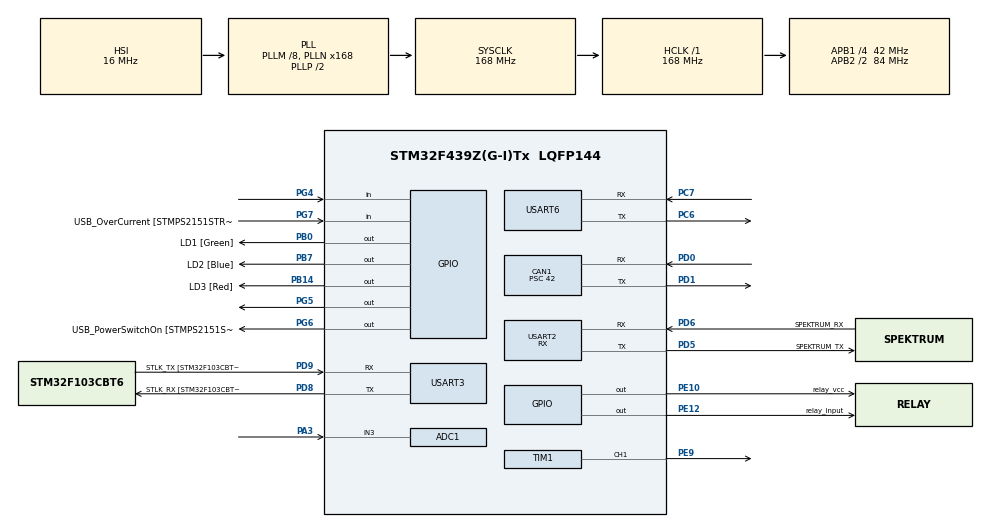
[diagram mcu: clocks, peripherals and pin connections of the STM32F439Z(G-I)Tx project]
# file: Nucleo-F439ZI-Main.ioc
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ADC1.Channel-2\#ChannelRegularConversion=ADC_CHANNEL_3
ADC1.NbrOfConversionFlag=1
ADC1.Rank-2\#ChannelRegularConversion=1
ADC1.SamplingTime-2\#ChannelRegularConversion=ADC_SAMPLETIME_3CYCLES
ADC1.master=1
CAN1.ABOM=ENABLE
CAN1.AWUM=ENABLE
CAN1.BS1=CAN_BS1_11TQ
CAN1.BS2=CAN_BS2_8TQ
CAN1.CalculateBaudRate=50000
CAN1.CalculateTimeBit=20000
CAN1.CalculateTimeQuantum=1000.0
CAN1.NART=ENABLE
CAN1.Prescaler=42
CAN1.TTCM=DISABLE
Mcu.Family=STM32F4
Mcu.Name=STM32F439Z(G-I)Tx
Mcu.Package=LQFP144
NVIC.CAN1_RX0_IRQn=true\:0\:0\:false\:false\:true\:true\:true\:true
NVIC.CAN1_RX1_IRQn=true\:0\:0\:false\:false\:true\:true\:true\:true
NVIC.CAN1_SCE_IRQn=true\:0\:0\:false\:false\:true\:true\:true\:true
NVIC.CAN1_TX_IRQn=true\:0\:0\:false\:false\:true\:true\:true\:true
NVIC.PriorityGroup=NVIC_PRIORITYGROUP_4
NVIC.RCC_IRQn=true\:0\:0\:false\:false\:true\:true\:false\:true
NVIC.TIM6_DAC_IRQn=true\:0\:0\:false\:false\:true\:true\:true\:true
NVIC.USART2_IRQn=true\:1\:0\:true\:false\:true\:true\:true\:true
PA1.GPIO_Label=RMII_REF_CLK [LAN8742A-CZ-TR_REFCLK0]
PA1.Signal=ETH_REF_CLK
PA10.GPIO_Label=USB_ID
PA10.Signal=USB_OTG_FS_ID
PA11.GPIO_Label=USB_DM
PA11.Signal=USB_OTG_FS_DM
PA12.GPIO_Label=USB_DP
PA12.Signal=USB_OTG_FS_DP
PA13.GPIO_Label=TMS
PA13.Mode=Serial_Wire
PA13.Signal=SYS_JTMS-SWDIO
PA14.GPIO_Label=TCK
PA14.Mode=Serial_Wire
PA14.Signal=SYS_JTCK-SWCLK
PA2.GPIO_Label=RMII_MDIO [LAN8742A-CZ-TR_MDIO]
PA2.Signal=ETH_MDIO
PA3.Signal=ADCx_IN3
PA7.GPIO_Label=RMII_CRS_DV [LAN8742A-CZ-TR_CRS_DV]
PA7.Signal=ETH_CRS_DV
PA8.GPIO_Label=USB_SOF [TP1]
PA8.Signal=USB_OTG_FS_SOF
PA9.GPIO_Label=USB_VBUS
PA9.Signal=USB_OTG_FS_VBUS
PB0.GPIO_Label=LD1 [Green]
PB0.Signal=GPIO_Output
PB13.GPIO_Label=RMII_TXD1 [LAN8742A-CZ-TR_TXD1]
PB13.Signal=ETH_TXD1
PB14.GPIO_Label=LD3 [Red]
PB14.Signal=GPIO_Output
PB7.GPIO_Label=LD2 [Blue]
PB7.Signal=GPIO_Output
PC1.GPIO_Label=RMII_MDC [LAN8742A-CZ-TR_MDC]
PC1.Signal=ETH_MDC
PC14/OSC32_IN.Mode=LSE-External-Oscillator
PC14/OSC32_IN.Signal=RCC_OSC32_IN
PC15/OSC32_OUT.Mode=LSE-External-Oscillator
PC15/OSC32_OUT.Signal=RCC_OSC32_OUT
PC4.GPIO_Label=RMII_RXD0 [LAN8742A-CZ-TR_RXD0]
PC4.Signal=ETH_RXD0
PC5.GPIO_Label=RMII_RXD1 [LAN8742A-CZ-TR_RXD1]
PC5.Signal=ETH_RXD1
PC6.Mode=Asynchronous
PC6.Signal=USART6_TX
PC7.Mode=Asynchronous
PC7.Signal=USART6_RX
PD0.Mode=CAN_Activate
PD0.Signal=CAN1_RX
PD1.Mode=CAN_Activate
PD1.Signal=CAN1_TX
PD5.GPIO_Label=SPEKTRUM_TX
PD5.Mode=Asynchronous
PD5.Signal=USART2_TX
PD6.GPIO_Label=SPEKTRUM_RX
PD6.Mode=Asynchronous
PD6.Signal=USART2_RX
PD8.GPIO_Label=STLK_RX [STM32F103CBT6_PA3]
PD8.Mode=Asynchronous
PD8.Signal=USART3_TX
PD9.GPIO_Label=STLK_TX [STM32F103CBT6_PA2]
PD9.Mode=Asynchronous
PD9.Signal=USART3_RX
PE10.GPIO_Label=relay_vcc
PE10.Signal=GPIO_Output
PE12.GPIO_Label=relay_input
PE12.Signal=GPIO_Output
PE9.Signal=S_TIM1_CH1
PG11.GPIO_Label=RMII_TX_EN [LAN8742A-CZ-TR_TXEN]
PG11.Signal=ETH_TX_EN
PG13.GPIO_Label=RMII_TXD0 [LAN8742A-CZ-TR_TXD0]
PG13.Signal=ETH_TXD0
PG4.Signal=GPIO_Input
PG5.Signal=GPIO_Output
PG6.GPIO_Label=USB_PowerSwitchOn [STMPS2151STR_EN]
PG6.Signal=GPIO_Output
PG7.GPIO_Label=USB_OverCurrent [STMPS2151STR_FAULT]
PG7.Signal=GPIO_Input
PH0/OSC_IN.GPIO_Label=MCO [STM32F103CBT6_PA8]
PH0/OSC_IN.Mode=HSE-External-Clock-Source
PH0/OSC_IN.Signal=RCC_OSC_IN
PH1/OSC_OUT.Mode=HSE-External-Clock-Source
PH1/OSC_OUT.Signal=RCC_OSC_OUT
ProjectManager.HeapSize=0x200
ProjectManager.StackSize=0x400
ProjectManager.TargetToolchain=STM32CubeIDE
RCC.48MHZClocksFreq_Value=48000000
RCC.AHBFreq_Value=168000000
RCC.APB1CLKDivider=RCC_HCLK_DIV4
RCC.APB1Freq_Value=42000000
RCC.APB1TimFreq_Value=84000000
RCC.APB2CLKDivider=RCC_HCLK_DIV2
RCC.APB2Freq_Value=84000000
RCC.APB2TimFreq_Value=168000000
RCC.CortexFreq_Value=168000000
RCC.HCLKFreq_Value=168000000
RCC.HSE_VALUE=8000000
RCC.HSI_VALUE=16000000
RCC.PLLM=8
RCC.PLLMUL=RCC_PLL_MUL9
RCC.PLLN=168
RCC.PLLQ=7
RCC.PRESCALERUSB=RCC_USBCLKSOURCE_PLL_DIV1_5
RCC.SYSCLKFreq_VALUE=168000000
RCC.SYSCLKSource=RCC_SYSCLKSOURCE_PLLCLK
RCC.SYSCLKSourceVirtual=RCC_SYSCLKSOURCE_PLLCLK
RCC.USBFreq_Value=48000000
RCC.VCOOutputFreq_Value=336000000
SH.ADCx_IN3.0=ADC1_IN3,IN3
SH.S_TIM1_CH1.0=TIM1_CH1,PWM Generation1 CH1
TIM1.Channel-PWM\ Generation1\ CH1=TIM_CHANNEL_1
TIM1.Period=200-1
TIM1.Prescaler=3*168-1
TIM6.AutoReloadPreload=TIM_AUTORELOAD_PRELOAD_DISABLE
TIM6.Period=10000
TIM6.Prescaler=168-1
USART2.Mode=MODE_RX
USART2.VirtualMode=VM_ASYNC
USART3.VirtualMode=VM_ASYNC
USART6.VirtualMode=VM_ASYNC
VP_TIM6_VS_ClockSourceINT.Mode=Enable_Timer
board=NUCLEO-F439ZI

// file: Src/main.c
/* USER CODE BEGIN Header */
/**
  ******************************************************************************
  * @file           : main.c
  * @brief          : Main program body
  ******************************************************************************
  * @attention
  *
  * Copyright (c) 2022 STMicroelectronics.
  * All rights reserved.
  *
  * This software is licensed under terms that can be found in the LICENSE file
  * in the root directory of this software component.
  * If no LICENSE file comes with this software, it is provided AS-IS.
  *
  ******************************************************************************
  */
/* USER CODE END Header */
#include "main.h"

/* USER CODE BEGIN Includes */
#include <stdio.h>
#include "app.h"
#include "av_com.h"

#include "terminal.h"
#include "utils.h"
#include "endianness.h"
/* USER CODE END Includes */

ADC_HandleTypeDef hadc1;

CAN_HandleTypeDef hcan1;

TIM_HandleTypeDef htim1;
TIM_HandleTypeDef htim6;

UART_HandleTypeDef huart2;
UART_HandleTypeDef huart3;
UART_HandleTypeDef huart6;

/* USER CODE BEGIN PV */
int throttle;
int throttle_min = 50;
int throttle_max = 2800;

float acc_percent;
float acc_limit = 0.5;

int speed_suppress_count = 0;
int speed_suppress_low = 3;
int speed_suppress_high = 5;

app_state_t app;
app_state_t *main_app;

CAN_TxHeaderTypeDef TxHeader;
CAN_RxHeaderTypeDef RxHeader;

uint32_t TxMailbox;

uint8_t TxData[8];
uint8_t RxData[8];

uint8_t UART_Rx_data[10];

/* USER CODE END PV */

void SystemClock_Config(void);
static void MX_GPIO_Init(void);
static void MX_USART3_UART_Init(void);
static void MX_USART2_UART_Init(void);
static void MX_TIM1_Init(void);
static void MX_CAN1_Init(void);
static void MX_ADC1_Init(void);
static void MX_USART6_UART_Init(void);
static void MX_TIM6_Init(void);

/* USER CODE BEGIN 0 */

int Debug_UART_Get_Byte() {
	if (__HAL_UART_GET_FLAG(&huart3, UART_FLAG_RXNE) == SET) {
		return (uint8_t) (huart3.Instance->DR & (uint8_t) 0x00FF);
	}
	return -1;
}

void HAL_TIM_PeriodElapsedCallback(TIM_HandleTypeDef *htim) {
	if (htim == &htim6) {
	  // get remote control speed
	  acc_percent = app.acc_percent;

	  if (acc_percent < -0.6){
		  TxData[1] = (int)0;
	  }
	  if (acc_percent >= -0.6 && acc_percent < -0.2){
		  TxData[1] = (int)1;
	  }
	  if (acc_percent >= -0.2){
		  TxData[1] = (int)2;
	  }

	  if (acc_percent < 0.00){
		  acc_percent = 0.00;
	  }

	  if (acc_percent > 1.00){
		  acc_percent = 1.00;
	  }

	  speed_suppress_count += 1;

	  if (speed_suppress_count < speed_suppress_low){
		  TIM1->CCR1 = 138 - 138 * acc_percent * acc_limit;
	  }
	  else if(speed_suppress_count < speed_suppress_high){
		  TIM1->CCR1 = 138;
	  }
	  else{
		  TIM1->CCR1 = 138;
		  speed_suppress_count = 0;
	  }

	  HAL_TIM_PWM_Start(&htim1, TIM_CHANNEL_1);

	  // send steer command over can bus
	  TxData[0] = (int)app.steering_angle;

	  // printf("steering angle desired %d \r\n", TxData[0]);

	  HAL_CAN_AddTxMessage(&hcan1, &TxHeader, TxData, &TxMailbox);
  }
}

/* USER CODE END 0 */

int main(void)
{

  /* MCU Configuration--------------------------------------------------------*/

  /* Reset of all peripherals, Initializes the Flash interface and the Systick. */
  HAL_Init();

  /* Configure the system clock */
  SystemClock_Config();

  /* Initialize all configured peripherals */
  MX_GPIO_Init();
  MX_USART3_UART_Init();
  MX_USART2_UART_Init();
  MX_TIM1_Init();
  MX_CAN1_Init();
  MX_ADC1_Init();
  MX_USART6_UART_Init();
  MX_TIM6_Init();
  /* USER CODE BEGIN 2 */

  main_app = &app;
  app_run(&app);

  HAL_TIM_Base_Start_IT(&htim6);
  av_com_start_receiving(&huart6);

  HAL_Delay(1000);

  /* USER CODE END 2 */

  /* Infinite loop */
  /* USER CODE BEGIN WHILE */
  while (1)
  {
//	  int temp = HAL_GPIO_ReadPin(GPIOG, Speed_Sensor_Pin);
//	  debug_printf("wheel speed sensor %d \r\n", temp);

//	  uint8_t message[] = "Hello World!!!"; //Data to send
//	  send_vehicle_status(&huart6, message, 14);
//	  HAL_Delay(200);
//
//	  int i;
//	  for (i=0;i < (sizeof (data_frame) /sizeof (data_frame[0]));i++) {
//	      debug_printf("%c",data_frame[i]);
//	  }
//	  debug_printf("\r\n");

	  if (1){
		 // Get throttle value
		  HAL_ADC_Start(&hadc1);
		  HAL_ADC_PollForConversion(&hadc1, HAL_MAX_DELAY);
		  throttle = HAL_ADC_GetValue(&hadc1);
		  acc_percent = (throttle_max - throttle) * 1.0 / (throttle_max - throttle_min) * 1.0;
		  acc_percent = 1.0 - acc_percent;

		  debug_printf("throttle %d \r\n", throttle);
	  } else{
//		  get remote control speed
		  acc_percent = app.acc_percent;
	  }
    /* USER CODE END WHILE */
  }

}

void SystemClock_Config(void)
{
  RCC_OscInitTypeDef RCC_OscInitStruct = {0};
  RCC_ClkInitTypeDef RCC_ClkInitStruct = {0};

  /** Configure the main internal regulator output voltage
  */
  __HAL_RCC_PWR_CLK_ENABLE();
  __HAL_PWR_VOLTAGESCALING_CONFIG(PWR_REGULATOR_VOLTAGE_SCALE1);

  /** Initializes the RCC Oscillators according to the specified parameters
  * in the RCC_OscInitTypeDef structure.
  */
  RCC_OscInitStruct.OscillatorType = RCC_OSCILLATORTYPE_HSI;
  RCC_OscInitStruct.HSIState = RCC_HSI_ON;
  RCC_OscInitStruct.HSICalibrationValue = RCC_HSICALIBRATION_DEFAULT;
  RCC_OscInitStruct.PLL.PLLState = RCC_PLL_ON;
  RCC_OscInitStruct.PLL.PLLSource = RCC_PLLSOURCE_HSI;
  RCC_OscInitStruct.PLL.PLLM = 8;
  RCC_OscInitStruct.PLL.PLLN = 168;
  RCC_OscInitStruct.PLL.PLLP = RCC_PLLP_DIV2;
  RCC_OscInitStruct.PLL.PLLQ = 7;
  if (HAL_RCC_OscConfig(&RCC_OscInitStruct) != HAL_OK)
  {
    Error_Handler();
  }

  /** Initializes the CPU, AHB and APB buses clocks
  */
  RCC_ClkInitStruct.ClockType = RCC_CLOCKTYPE_HCLK|RCC_CLOCKTYPE_SYSCLK
                              |RCC_CLOCKTYPE_PCLK1|RCC_CLOCKTYPE_PCLK2;
  RCC_ClkInitStruct.SYSCLKSource = RCC_SYSCLKSOURCE_PLLCLK;
  RCC_ClkInitStruct.AHBCLKDivider = RCC_SYSCLK_DIV1;
  RCC_ClkInitStruct.APB1CLKDivider = RCC_HCLK_DIV4;
  RCC_ClkInitStruct.APB2CLKDivider = RCC_HCLK_DIV2;

  if (HAL_RCC_ClockConfig(&RCC_ClkInitStruct, FLASH_LATENCY_5) != HAL_OK)
  {
    Error_Handler();
  }
}

static void MX_ADC1_Init(void)
{

  ADC_ChannelConfTypeDef sConfig = {0};

  /** Configure the global features of the ADC (Clock, Resolution, Data Alignment and number of conversion)
  */
  hadc1.Instance = ADC1;
  hadc1.Init.ClockPrescaler = ADC_CLOCK_SYNC_PCLK_DIV4;
  hadc1.Init.Resolution = ADC_RESOLUTION_12B;
  hadc1.Init.ScanConvMode = DISABLE;
  hadc1.Init.ContinuousConvMode = DISABLE;
  hadc1.Init.DiscontinuousConvMode = DISABLE;
  hadc1.Init.ExternalTrigConvEdge = ADC_EXTERNALTRIGCONVEDGE_NONE;
  hadc1.Init.ExternalTrigConv = ADC_SOFTWARE_START;
  hadc1.Init.DataAlign = ADC_DATAALIGN_RIGHT;
  hadc1.Init.NbrOfConversion = 1;
  hadc1.Init.DMAContinuousRequests = DISABLE;
  hadc1.Init.EOCSelection = ADC_EOC_SINGLE_CONV;
  if (HAL_ADC_Init(&hadc1) != HAL_OK)
  {
    Error_Handler();
  }

  /** Configure for the selected ADC regular channel its corresponding rank in the sequencer and its sample time.
  */
  sConfig.Channel = ADC_CHANNEL_3;
  sConfig.Rank = 1;
  sConfig.SamplingTime = ADC_SAMPLETIME_3CYCLES;
  if (HAL_ADC_ConfigChannel(&hadc1, &sConfig) != HAL_OK)
  {
    Error_Handler();
  }

}

static void MX_CAN1_Init(void)
{

  /* USER CODE BEGIN CAN1_Init 0 */
  TxHeader.DLC = 4;
  TxHeader.ExtId = 0;
  TxHeader.IDE = CAN_ID_STD;
  TxHeader.RTR = CAN_RTR_DATA;
  TxHeader.StdId = 0x104;
  TxHeader.TransmitGlobalTime = DISABLE;

  /* USER CODE END CAN1_Init 0 */

  hcan1.Instance = CAN1;
  hcan1.Init.Prescaler = 42;
  hcan1.Init.Mode = CAN_MODE_NORMAL;
  hcan1.Init.SyncJumpWidth = CAN_SJW_1TQ;
  hcan1.Init.TimeSeg1 = CAN_BS1_11TQ;
  hcan1.Init.TimeSeg2 = CAN_BS2_8TQ;
  hcan1.Init.TimeTriggeredMode = DISABLE;
  hcan1.Init.AutoBusOff = ENABLE;
  hcan1.Init.AutoWakeUp = ENABLE;
  hcan1.Init.AutoRetransmission = ENABLE;
  hcan1.Init.ReceiveFifoLocked = DISABLE;
  hcan1.Init.TransmitFifoPriority = DISABLE;
  if (HAL_CAN_Init(&hcan1) != HAL_OK)
  {
    Error_Handler();
  }
  /* USER CODE BEGIN CAN1_Init 2 */

  CAN_FilterTypeDef canfilterconfig;

  canfilterconfig.FilterActivation = CAN_FILTER_ENABLE;
  canfilterconfig.FilterBank = 10;
  canfilterconfig.FilterFIFOAssignment = CAN_RX_FIFO0;
  canfilterconfig.FilterIdHigh = 0;
  canfilterconfig.FilterIdLow = 0x0000;
  canfilterconfig.FilterMaskIdHigh = 0;
  canfilterconfig.FilterMaskIdLow = 0x0000;
  canfilterconfig.FilterMode = CAN_FILTERMODE_IDMASK;
  canfilterconfig.FilterScale = CAN_FILTERSCALE_32BIT;
  canfilterconfig.SlaveStartFilterBank = 0;

  HAL_CAN_ConfigFilter(&hcan1, &canfilterconfig);
  HAL_CAN_Start(&hcan1);
  HAL_CAN_ActivateNotification(&hcan1, CAN_IT_RX_FIFO0_MSG_PENDING);

  /* USER CODE END CAN1_Init 2 */

}

static void MX_TIM1_Init(void)
{

  TIM_MasterConfigTypeDef sMasterConfig = {0};
  TIM_OC_InitTypeDef sConfigOC = {0};
  TIM_BreakDeadTimeConfigTypeDef sBreakDeadTimeConfig = {0};

  htim1.Instance = TIM1;
  htim1.Init.Prescaler = 3*168-1;
  htim1.Init.CounterMode = TIM_COUNTERMODE_UP;
  htim1.Init.Period = 200-1;
  htim1.Init.ClockDivision = TIM_CLOCKDIVISION_DIV1;
  htim1.Init.RepetitionCounter = 0;
  htim1.Init.AutoReloadPreload = TIM_AUTORELOAD_PRELOAD_DISABLE;
  if (HAL_TIM_PWM_Init(&htim1) != HAL_OK)
  {
    Error_Handler();
  }
  sMasterConfig.MasterOutputTrigger = TIM_TRGO_RESET;
  sMasterConfig.MasterSlaveMode = TIM_MASTERSLAVEMODE_DISABLE;
  if (HAL_TIMEx_MasterConfigSynchronization(&htim1, &sMasterConfig) != HAL_OK)
  {
    Error_Handler();
  }
  sConfigOC.OCMode = TIM_OCMODE_PWM1;
  sConfigOC.Pulse = 0;
  sConfigOC.OCPolarity = TIM_OCPOLARITY_HIGH;
  sConfigOC.OCNPolarity = TIM_OCNPOLARITY_HIGH;
  sConfigOC.OCFastMode = TIM_OCFAST_DISABLE;
  sConfigOC.OCIdleState = TIM_OCIDLESTATE_RESET;
  sConfigOC.OCNIdleState = TIM_OCNIDLESTATE_RESET;
  if (HAL_TIM_PWM_ConfigChannel(&htim1, &sConfigOC, TIM_CHANNEL_1) != HAL_OK)
  {
    Error_Handler();
  }
  sBreakDeadTimeConfig.OffStateRunMode = TIM_OSSR_DISABLE;
  sBreakDeadTimeConfig.OffStateIDLEMode = TIM_OSSI_DISABLE;
  sBreakDeadTimeConfig.LockLevel = TIM_LOCKLEVEL_OFF;
  sBreakDeadTimeConfig.DeadTime = 0;
  sBreakDeadTimeConfig.BreakState = TIM_BREAK_DISABLE;
  sBreakDeadTimeConfig.BreakPolarity = TIM_BREAKPOLARITY_HIGH;
  sBreakDeadTimeConfig.AutomaticOutput = TIM_AUTOMATICOUTPUT_DISABLE;
  if (HAL_TIMEx_ConfigBreakDeadTime(&htim1, &sBreakDeadTimeConfig) != HAL_OK)
  {
    Error_Handler();
  }
  HAL_TIM_MspPostInit(&htim1);

}

static void MX_TIM6_Init(void)
{

  TIM_MasterConfigTypeDef sMasterConfig = {0};

  htim6.Instance = TIM6;
  htim6.Init.Prescaler = 168-1;
  htim6.Init.CounterMode = TIM_COUNTERMODE_UP;
  htim6.Init.Period = 10000;
  htim6.Init.AutoReloadPreload = TIM_AUTORELOAD_PRELOAD_DISABLE;
  if (HAL_TIM_Base_Init(&htim6) != HAL_OK)
  {
    Error_Handler();
  }
  sMasterConfig.MasterOutputTrigger = TIM_TRGO_RESET;
  sMasterConfig.MasterSlaveMode = TIM_MASTERSLAVEMODE_DISABLE;
  if (HAL_TIMEx_MasterConfigSynchronization(&htim6, &sMasterConfig) != HAL_OK)
  {
    Error_Handler();
  }

}

static void MX_USART2_UART_Init(void)
{

  huart2.Instance = USART2;
  huart2.Init.BaudRate = 115200;
  huart2.Init.WordLength = UART_WORDLENGTH_8B;
  huart2.Init.StopBits = UART_STOPBITS_1;
  huart2.Init.Parity = UART_PARITY_NONE;
  huart2.Init.Mode = UART_MODE_RX;
  huart2.Init.HwFlowCtl = UART_HWCONTROL_NONE;
  huart2.Init.OverSampling = UART_OVERSAMPLING_16;
  if (HAL_UART_Init(&huart2) != HAL_OK)
  {
    Error_Handler();
  }

}

static void MX_USART3_UART_Init(void)
{

  huart3.Instance = USART3;
  huart3.Init.BaudRate = 115200;
  huart3.Init.WordLength = UART_WORDLENGTH_8B;
  huart3.Init.StopBits = UART_STOPBITS_1;
  huart3.Init.Parity = UART_PARITY_NONE;
  huart3.Init.Mode = UART_MODE_TX_RX;
  huart3.Init.HwFlowCtl = UART_HWCONTROL_NONE;
  huart3.Init.OverSampling = UART_OVERSAMPLING_16;
  if (HAL_UART_Init(&huart3) != HAL_OK)
  {
    Error_Handler();
  }

}

static void MX_USART6_UART_Init(void)
{

  huart6.Instance = USART6;
  huart6.Init.BaudRate = 115200;
  huart6.Init.WordLength = UART_WORDLENGTH_8B;
  huart6.Init.StopBits = UART_STOPBITS_1;
  huart6.Init.Parity = UART_PARITY_NONE;
  huart6.Init.Mode = UART_MODE_TX_RX;
  huart6.Init.HwFlowCtl = UART_HWCONTROL_NONE;
  huart6.Init.OverSampling = UART_OVERSAMPLING_16;
  if (HAL_UART_Init(&huart6) != HAL_OK)
  {
    Error_Handler();
  }

}

static void MX_GPIO_Init(void)
{
  GPIO_InitTypeDef GPIO_InitStruct = {0};

  /* GPIO Ports Clock Enable */
  __HAL_RCC_GPIOC_CLK_ENABLE();
  __HAL_RCC_GPIOH_CLK_ENABLE();
  __HAL_RCC_GPIOA_CLK_ENABLE();
  __HAL_RCC_GPIOB_CLK_ENABLE();
  __HAL_RCC_GPIOE_CLK_ENABLE();
  __HAL_RCC_GPIOD_CLK_ENABLE();
  __HAL_RCC_GPIOG_CLK_ENABLE();

  /*Configure GPIO pin Output Level */
  HAL_GPIO_WritePin(GPIOB, LD1_Pin|LD3_Pin|LD2_Pin, GPIO_PIN_RESET);

  /*Configure GPIO pin Output Level */
  HAL_GPIO_WritePin(GPIOG, GPIO_PIN_5|USB_PowerSwitchOn_Pin, GPIO_PIN_RESET);

  /*Configure GPIO pins : RMII_MDC_Pin RMII_RXD0_Pin RMII_RXD1_Pin */
  GPIO_InitStruct.Pin = RMII_MDC_Pin|RMII_RXD0_Pin|RMII_RXD1_Pin;
  GPIO_InitStruct.Mode = GPIO_MODE_AF_PP;
  GPIO_InitStruct.Pull = GPIO_NOPULL;
  GPIO_InitStruct.Speed = GPIO_SPEED_FREQ_VERY_HIGH;
  GPIO_InitStruct.Alternate = GPIO_AF11_ETH;
  HAL_GPIO_Init(GPIOC, &GPIO_InitStruct);

  /*Configure GPIO pins : RMII_REF_CLK_Pin RMII_MDIO_Pin RMII_CRS_DV_Pin */
  GPIO_InitStruct.Pin = RMII_REF_CLK_Pin|RMII_MDIO_Pin|RMII_CRS_DV_Pin;
  GPIO_InitStruct.Mode = GPIO_MODE_AF_PP;
  GPIO_InitStruct.Pull = GPIO_NOPULL;
  GPIO_InitStruct.Speed = GPIO_SPEED_FREQ_VERY_HIGH;
  GPIO_InitStruct.Alternate = GPIO_AF11_ETH;
  HAL_GPIO_Init(GPIOA, &GPIO_InitStruct);

  /*Configure GPIO pins : LD1_Pin LD3_Pin LD2_Pin */
  GPIO_InitStruct.Pin = LD1_Pin|LD3_Pin|LD2_Pin;
  GPIO_InitStruct.Mode = GPIO_MODE_OUTPUT_PP;
  GPIO_InitStruct.Pull = GPIO_NOPULL;
  GPIO_InitStruct.Speed = GPIO_SPEED_FREQ_LOW;
  HAL_GPIO_Init(GPIOB, &GPIO_InitStruct);

  /*Configure GPIO pin : RMII_TXD1_Pin */
  GPIO_InitStruct.Pin = RMII_TXD1_Pin;
  GPIO_InitStruct.Mode = GPIO_MODE_AF_PP;
  GPIO_InitStruct.Pull = GPIO_NOPULL;
  GPIO_InitStruct.Speed = GPIO_SPEED_FREQ_VERY_HIGH;
  GPIO_InitStruct.Alternate = GPIO_AF11_ETH;
  HAL_GPIO_Init(RMII_TXD1_GPIO_Port, &GPIO_InitStruct);

  /*Configure GPIO pins : PG4 USB_OverCurrent_Pin Speed_Sensor_Pin */
  GPIO_InitStruct.Pin = GPIO_PIN_4|USB_OverCurrent_Pin|Speed_Sensor_Pin;
  GPIO_InitStruct.Mode = GPIO_MODE_INPUT;
  GPIO_InitStruct.Pull = GPIO_NOPULL;
  HAL_GPIO_Init(GPIOG, &GPIO_InitStruct);

  /*Configure GPIO pins : PG5 USB_PowerSwitchOn_Pin */
  GPIO_InitStruct.Pin = GPIO_PIN_5|USB_PowerSwitchOn_Pin;
  GPIO_InitStruct.Mode = GPIO_MODE_OUTPUT_PP;
  GPIO_InitStruct.Pull = GPIO_NOPULL;
  GPIO_InitStruct.Speed = GPIO_SPEED_FREQ_LOW;
  HAL_GPIO_Init(GPIOG, &GPIO_InitStruct);

  /*Configure GPIO pins : USB_SOF_Pin USB_ID_Pin USB_DM_Pin USB_DP_Pin */
  GPIO_InitStruct.Pin = USB_SOF_Pin|USB_ID_Pin|USB_DM_Pin|USB_DP_Pin;
  GPIO_InitStruct.Mode = GPIO_MODE_AF_PP;
  GPIO_InitStruct.Pull = GPIO_NOPULL;
  GPIO_InitStruct.Speed = GPIO_SPEED_FREQ_VERY_HIGH;
  GPIO_InitStruct.Alternate = GPIO_AF10_OTG_FS;
  HAL_GPIO_Init(GPIOA, &GPIO_InitStruct);

  /*Configure GPIO pin : USB_VBUS_Pin */
  GPIO_InitStruct.Pin = USB_VBUS_Pin;
  GPIO_InitStruct.Mode = GPIO_MODE_INPUT;
  GPIO_InitStruct.Pull = GPIO_NOPULL;
  HAL_GPIO_Init(USB_VBUS_GPIO_Port, &GPIO_InitStruct);

  /*Configure GPIO pins : RMII_TX_EN_Pin RMII_TXD0_Pin */
  GPIO_InitStruct.Pin = RMII_TX_EN_Pin|RMII_TXD0_Pin;
  GPIO_InitStruct.Mode = GPIO_MODE_AF_PP;
  GPIO_InitStruct.Pull = GPIO_NOPULL;
  GPIO_InitStruct.Speed = GPIO_SPEED_FREQ_VERY_HIGH;
  GPIO_InitStruct.Alternate = GPIO_AF11_ETH;
  HAL_GPIO_Init(GPIOG, &GPIO_InitStruct);

}

void Error_Handler(void)
{
  /* USER CODE BEGIN Error_Handler_Debug */
	/* User can add his own implementation to report the HAL error return state */
	__disable_irq();
	HAL_GPIO_WritePin(LD1_GPIO_Port, LD1_Pin, GPIO_PIN_SET);
	HAL_GPIO_WritePin(LD2_GPIO_Port, LD2_Pin, GPIO_PIN_SET);
	HAL_GPIO_WritePin(LD3_GPIO_Port, LD3_Pin, GPIO_PIN_SET);

	HAL_Delay(500);

	HAL_GPIO_WritePin(LD1_GPIO_Port, LD1_Pin, GPIO_PIN_RESET);
	HAL_GPIO_WritePin(LD2_GPIO_Port, LD2_Pin, GPIO_PIN_RESET);
	HAL_GPIO_WritePin(LD3_GPIO_Port, LD3_Pin, GPIO_PIN_RESET);

	HAL_Delay(500);
//	while (1) {
//	}
  /* USER CODE END Error_Handler_Debug */
}
